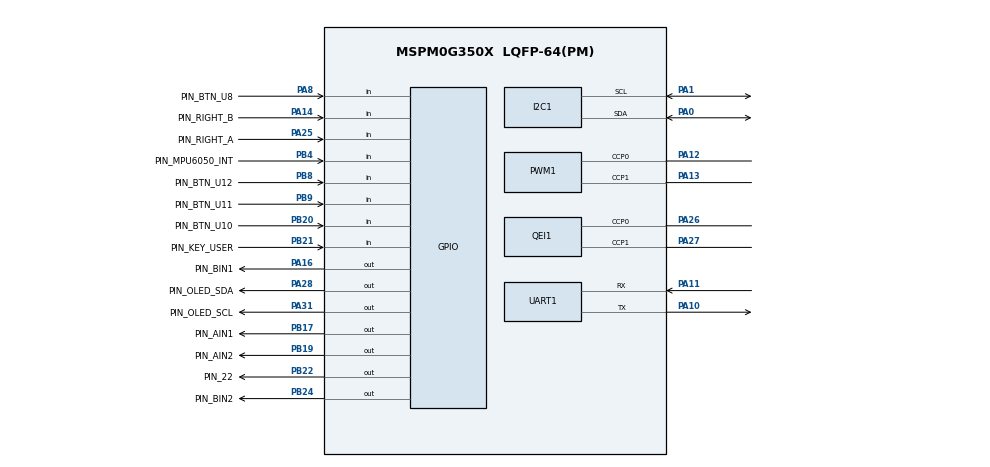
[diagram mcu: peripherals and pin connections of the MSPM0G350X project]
/**
 * @cliArgs --device "MSPM0G350X" --part "Default" --package "LQFP-64(PM)" --product "mspm0_sdk@2.04.00.06"
 * @versions {"tool":"1.23.1+4034"}
 */

/**
 * Import the modules used in this configuration.
 */
const GPIO   = scripting.addModule("/ti/driverlib/GPIO", {}, false);
const GPIO1  = GPIO.addInstance();
const GPIO2  = GPIO.addInstance();
const GPIO3  = GPIO.addInstance();
const GPIO4  = GPIO.addInstance();
const GPIO5  = GPIO.addInstance();
const GPIO6  = GPIO.addInstance();
const GPIO7  = GPIO.addInstance();
const GPIO8  = GPIO.addInstance();
const GPIO9  = GPIO.addInstance();
const GPIO10 = GPIO.addInstance();
const I2C    = scripting.addModule("/ti/driverlib/I2C", {}, false);
const I2C1   = I2C.addInstance();
const PWM    = scripting.addModule("/ti/driverlib/PWM", {}, false);
const PWM1   = PWM.addInstance();
const QEI    = scripting.addModule("/ti/driverlib/QEI", {}, false);
const QEI1   = QEI.addInstance();
const SYSCTL = scripting.addModule("/ti/driverlib/SYSCTL");
const TIMER  = scripting.addModule("/ti/driverlib/TIMER", {}, false);
const TIMER1 = TIMER.addInstance();
const UART   = scripting.addModule("/ti/driverlib/UART", {}, false);
const UART1  = UART.addInstance();

/**
 * Write custom configuration values to the imported modules.
 */
const divider9       = system.clockTree["UDIV"];
divider9.divideValue = 2;

const gate7  = system.clockTree["MFCLKGATE"];
gate7.enable = true;

const multiplier2         = system.clockTree["PLL_QDIV"];
multiplier2.multiplyValue = 4;

const mux4       = system.clockTree["EXHFMUX"];
mux4.inputSelect = "EXHFMUX_XTAL";

const mux8       = system.clockTree["HSCLKMUX"];
mux8.inputSelect = "HSCLKMUX_SYSPLL0";

const mux12       = system.clockTree["SYSPLLMUX"];
mux12.inputSelect = "zSYSPLLMUX_HFCLK";

const pinFunction4        = system.clockTree["HFXT"];
pinFunction4.inputFreq    = 40;
pinFunction4.enable       = true;
pinFunction4.HFXTStartup  = 10;
pinFunction4.HFCLKMonitor = true;

GPIO1.$name                         = "LED";
GPIO1.port                          = "PORTB";
GPIO1.associatedPins[0].$name       = "PIN_22";
GPIO1.associatedPins[0].pin.$assign = "PB22";

const Board = scripting.addModule("/ti/driverlib/Board", {}, false);

GPIO2.$name                               = "GPIO_MPU6050_INT";
GPIO2.port                                = "PORTB";
GPIO2.associatedPins[0].$name             = "PIN_MPU6050_INT";
GPIO2.associatedPins[0].direction         = "INPUT";
GPIO2.associatedPins[0].internalResistor  = "PULL_UP";
GPIO2.associatedPins[0].interruptEn       = true;
GPIO2.associatedPins[0].interruptPriority = "3";
GPIO2.associatedPins[0].polarity          = "FALL";
GPIO2.associatedPins[0].pin.$assign       = "PB4";

GPIO3.$name                         = "GPIO_OLED_SW_I2C";
GPIO3.associatedPins.create(2);
GPIO3.associatedPins[0].$name       = "PIN_OLED_SDA";
GPIO3.associatedPins[0].pin.$assign = "PA28";
GPIO3.associatedPins[1].$name       = "PIN_OLED_SCL";
GPIO3.associatedPins[1].pin.$assign = "PA31";

GPIO4.$name                         = "GPIO_TB6612";
GPIO4.associatedPins.create(4);
GPIO4.associatedPins[0].$name       = "PIN_AIN1";
GPIO4.associatedPins[0].pin.$assign = "PB17";
GPIO4.associatedPins[1].$name       = "PIN_AIN2";
GPIO4.associatedPins[1].pin.$assign = "PB19";
GPIO4.associatedPins[2].$name       = "PIN_BIN1";
GPIO4.associatedPins[2].pin.$assign = "PA16";
GPIO4.associatedPins[3].$name       = "PIN_BIN2";
GPIO4.associatedPins[3].pin.$assign = "PB24";

GPIO5.$name                              = "GPIO_KEY_USER";
GPIO5.associatedPins[0].$name            = "PIN_KEY_USER";
GPIO5.associatedPins[0].direction        = "INPUT";
GPIO5.associatedPins[0].internalResistor = "PULL_UP";
GPIO5.associatedPins[0].pin.$assign      = "PB21";

GPIO6.$name                               = "GPIO_ENCODER_RIGHT";
GPIO6.associatedPins.create(2);
GPIO6.associatedPins[0].$name             = "PIN_RIGHT_A";
GPIO6.associatedPins[0].direction         = "INPUT";
GPIO6.associatedPins[0].internalResistor  = "PULL_UP";
GPIO6.associatedPins[0].interruptEn       = true;
GPIO6.associatedPins[0].interruptPriority = "3";
GPIO6.associatedPins[0].polarity          = "RISE_FALL";
GPIO6.associatedPins[0].pin.$assign       = "PA25";
GPIO6.associatedPins[1].$name             = "PIN_RIGHT_B";
GPIO6.associatedPins[1].direction         = "INPUT";
GPIO6.associatedPins[1].internalResistor  = "PULL_UP";
GPIO6.associatedPins[1].interruptEn       = true;
GPIO6.associatedPins[1].interruptPriority = "3";
GPIO6.associatedPins[1].polarity          = "RISE_FALL";
GPIO6.associatedPins[1].pin.$assign       = "PA14";

GPIO7.$name                              = "GPIO_BTN_U8";
GPIO7.port                               = "PORTA";
GPIO7.associatedPins[0].$name            = "PIN_BTN_U8";
GPIO7.associatedPins[0].direction        = "INPUT";
GPIO7.associatedPins[0].internalResistor = "PULL_UP";
GPIO7.associatedPins[0].pin.$assign      = "PA8";

GPIO8.$name                              = "GPIO_BTN_U10";
GPIO8.port                               = "PORTB";
GPIO8.associatedPins[0].$name            = "PIN_BTN_U10";
GPIO8.associatedPins[0].direction        = "INPUT";
GPIO8.associatedPins[0].internalResistor = "PULL_UP";
GPIO8.associatedPins[0].pin.$assign      = "PB20";

GPIO9.$name                              = "GPIO_BTN_U11";
GPIO9.port                               = "PORTB";
GPIO9.associatedPins[0].$name            = "PIN_BTN_U11";
GPIO9.associatedPins[0].direction        = "INPUT";
GPIO9.associatedPins[0].internalResistor = "PULL_UP";
GPIO9.associatedPins[0].pin.$assign      = "PB9";

GPIO10.$name                              = "GPIO_BTN_U12";
GPIO10.port                               = "PORTB";
GPIO10.associatedPins[0].$name            = "PIN_BTN_U12";
GPIO10.associatedPins[0].direction        = "INPUT";
GPIO10.associatedPins[0].internalResistor = "PULL_UP";
GPIO10.associatedPins[0].pin.$assign      = "PB8";

I2C1.$name                     = "I2C_0";
I2C1.basicEnableController     = true;
I2C1.peripheral.$assign        = "I2C0";
I2C1.peripheral.sdaPin.$assign = "PA0";
I2C1.peripheral.sclPin.$assign = "PA1";
I2C1.sdaPinConfig.$name        = "ti_driverlib_gpio_GPIOPinGeneric2";
I2C1.sclPinConfig.$name        = "ti_driverlib_gpio_GPIOPinGeneric3";

PWM1.$name                              = "PWM_TB6612";
PWM1.timerCount                         = 2000;
PWM1.peripheral.$assign                 = "TIMG0";
PWM1.peripheral.ccp0Pin.$assign         = "PA12";
PWM1.peripheral.ccp1Pin.$assign         = "PA13";
PWM1.PWM_CHANNEL_0.$name                = "ti_driverlib_pwm_PWMTimerCC0";
PWM1.PWM_CHANNEL_1.$name                = "ti_driverlib_pwm_PWMTimerCC1";
PWM1.ccp0PinConfig.direction            = scripting.forceWrite("OUTPUT");
PWM1.ccp0PinConfig.hideOutputInversion  = scripting.forceWrite(false);
PWM1.ccp0PinConfig.onlyInternalResistor = scripting.forceWrite(false);
PWM1.ccp0PinConfig.passedPeripheralType = scripting.forceWrite("Digital");
PWM1.ccp0PinConfig.$name                = "ti_driverlib_gpio_GPIOPinGeneric4";
PWM1.ccp1PinConfig.direction            = scripting.forceWrite("OUTPUT");
PWM1.ccp1PinConfig.hideOutputInversion  = scripting.forceWrite(false);
PWM1.ccp1PinConfig.onlyInternalResistor = scripting.forceWrite(false);
PWM1.ccp1PinConfig.passedPeripheralType = scripting.forceWrite("Digital");
PWM1.ccp1PinConfig.$name                = "ti_driverlib_gpio_GPIOPinGeneric5";

QEI1.$name                              = "QEI_ENCODER_LEFT";
QEI1.peripheral.$assign                 = "TIMG8";
QEI1.peripheral.ccp0Pin.$assign         = "PA26";
QEI1.peripheral.ccp1Pin.$assign         = "PA27";
QEI1.ccp0PinConfig.hideOutputInversion  = scripting.forceWrite(false);
QEI1.ccp0PinConfig.onlyInternalResistor = scripting.forceWrite(false);
QEI1.ccp0PinConfig.passedPeripheralType = scripting.forceWrite("Digital");
QEI1.ccp0PinConfig.$name                = "ti_driverlib_gpio_GPIOPinGeneric6";
QEI1.ccp1PinConfig.hideOutputInversion  = scripting.forceWrite(false);
QEI1.ccp1PinConfig.onlyInternalResistor = scripting.forceWrite(false);
QEI1.ccp1PinConfig.passedPeripheralType = scripting.forceWrite("Digital");
QEI1.ccp1PinConfig.$name                = "ti_driverlib_gpio_GPIOPinGeneric7";

SYSCTL.forceDefaultClkConfig = true;
SYSCTL.clockTreeEn           = true;

TIMER1.$name              = "TIMER_0";
TIMER1.timerPeriod        = "10 ms";
TIMER1.timerMode          = "PERIODIC";
TIMER1.interrupts         = ["ZERO"];
TIMER1.peripheral.$assign = "TIMG12";

UART1.$name                    = "UART_0";
UART1.enabledInterrupts        = ["RX"];
UART1.peripheral.rxPin.$assign = "PA11";
UART1.peripheral.txPin.$assign = "PA10";
UART1.txPinConfig.$name        = "ti_driverlib_gpio_GPIOPinGeneric0";
UART1.rxPinConfig.$name        = "ti_driverlib_gpio_GPIOPinGeneric1";

/**
 * Pinmux solution for unlocked pins/peripherals. This ensures that minor changes to the automatic solver in a future
 * version of the tool will not impact the pinmux you originally saw.  These lines can be completely deleted in order to
 * re-solve from scratch.
 */
pinFunction4.peripheral.$suggestSolution           = "SYSCTL";
pinFunction4.peripheral.hfxInPin.$suggestSolution  = "PA5";
pinFunction4.peripheral.hfxOutPin.$suggestSolution = "PA6";
Board.peripheral.$suggestSolution                  = "DEBUGSS";
Board.peripheral.swclkPin.$suggestSolution         = "PA20";
Board.peripheral.swdioPin.$suggestSolution         = "PA19";
UART1.peripheral.$suggestSolution                  = "UART0";
